AUTOSAR XML (schema 00046)
package /ComponentTypes
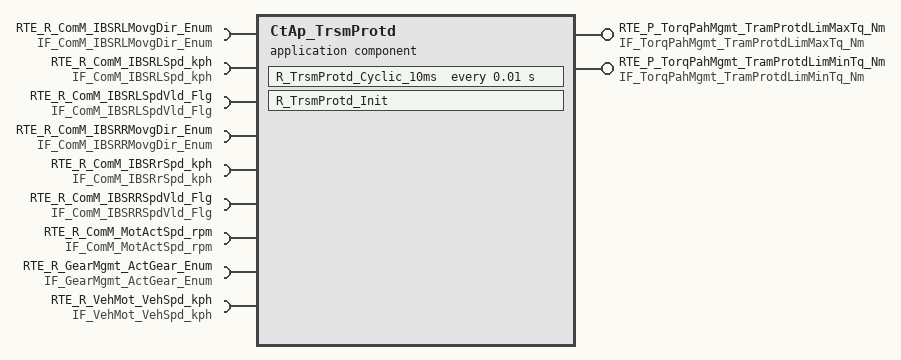
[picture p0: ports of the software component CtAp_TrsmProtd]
  application sw component type CtAp_TrsmProtd
    provide port RTE_P_TorqPahMgmt_TramProtdLimMaxTq_Nm: nonqueued-sender-com-spec=tec_TorqPahMgmt_TramProtdLmtMaxTq_Nm, provided-interface=IF_TorqPahMgmt_TramProtdLimMaxTq_Nm
    provide port RTE_P_TorqPahMgmt_TramProtdLimMinTq_Nm: nonqueued-sender-com-spec=tec_TorqPahMgmt_TramProtdLmtMinTq_Nm, provided-interface=IF_TorqPahMgmt_TramProtdLimMinTq_Nm
    9 x require port:
      RTE_R_ComM_IBSRLMovgDir_Enum: nonqueued-receiver-com-spec{data-element=tec_ComM_IBSRLMovgDir_Enum, filter=data-filter-type=ALWAYS}, required-interface=IF_ComM_IBSRLMovgDir_Enum
      RTE_R_ComM_IBSRLSpd_kph: nonqueued-receiver-com-spec{data-element=tec_ComM_IBSRLSpd_kph, filter=data-filter-type=ALWAYS}, required-interface=IF_ComM_IBSRLSpd_kph
      RTE_R_ComM_IBSRLSpdVld_Flg: nonqueued-receiver-com-spec{data-element=tec_ComM_IBSRLSpdVld_Flg, filter=data-filter-type=ALWAYS}, required-interface=IF_ComM_IBSRLSpdVld_Flg
      RTE_R_ComM_IBSRRMovgDir_Enum: nonqueued-receiver-com-spec{data-element=tec_ComM_IBSRRMovgDir_Enum, filter=data-filter-type=ALWAYS}, required-interface=IF_ComM_IBSRRMovgDir_Enum
      RTE_R_ComM_IBSRrSpd_kph: nonqueued-receiver-com-spec{data-element=tec_ComM_IBSRRSpd_kph, filter=data-filter-type=ALWAYS}, required-interface=IF_ComM_IBSRrSpd_kph
      RTE_R_ComM_IBSRRSpdVld_Flg: nonqueued-receiver-com-spec{data-element=tec_ComM_IBSRRSpdVld_Flg, filter=data-filter-type=ALWAYS}, required-interface=IF_ComM_IBSRRSpdVld_Flg
      RTE_R_ComM_MotActSpd_rpm: nonqueued-receiver-com-spec{data-element=tec_ComM_MotActSpd_rpm, filter=data-filter-type=ALWAYS}, required-interface=IF_ComM_MotActSpd_rpm
      RTE_R_GearMgmt_ActGear_Enum: nonqueued-receiver-com-spec{data-element=tec_GearMgmt_ActGear_Enum, filter=data-filter-type=ALWAYS}, required-interface=IF_GearMgmt_ActGear_Enum
      RTE_R_VehMot_VehSpd_kph: nonqueued-receiver-com-spec{data-element=tec_VehMot_VehSpd_kph, filter=data-filter-type=ALWAYS}, required-interface=IF_VehMot_VehSpd_kph
    behavior CtAp_TrsmProtd_InternalBehavior
      timing event TMT_R_TrsmProtd_Cyclic_10ms: start-on-event=R_TrsmProtd_Cyclic_10ms, period=0.01
      init event CtAp_TrsmProtd_InitEvent: start-on-event=R_TrsmProtd_Init
      runnable R_TrsmProtd_Cyclic_10ms
        data-receive-point-by-arguments:
          9 x access:
            REC_RTE_R_ComM_IBSRLMovgDir_Enum_tec_ComM_IBSRLMovgDir_Enum: accessed-variable=RTE_R_ComM_IBSRLMovgDir_Enum.tec_ComM_IBSRLMovgDir_Enum
            REC_RTE_R_ComM_IBSRLSpd_kph_tec_ComM_IBSRLSpd_kph: accessed-variable=RTE_R_ComM_IBSRLSpd_kph.tec_ComM_IBSRLSpd_kph
            REC_RTE_R_Comm_IBSRLSpdVld_Flg_tec_ComM_IBSRLSpdVld_Flg: accessed-variable=RTE_R_ComM_IBSRLSpdVld_Flg.tec_ComM_IBSRLSpdVld_Flg
            REC_RTE_R_ComM_IBSRRMovgDir_Enum_tec_ComM_IBSRRMovgDir_Enum: accessed-variable=RTE_R_ComM_IBSRRMovgDir_Enum.tec_ComM_IBSRRMovgDir_Enum
            REC_RTE_R_Comm_IBSRrSpd_kph_tec_ComM_IBSRRSpd_kph: accessed-variable=RTE_R_ComM_IBSRrSpd_kph.tec_ComM_IBSRRSpd_kph
            REC_RTE_R_Comm_IBSRRSpdVld_Flg_tec_ComM_IBSRRSpdVld_Flg: accessed-variable=RTE_R_ComM_IBSRRSpdVld_Flg.tec_ComM_IBSRRSpdVld_Flg
            REC_RTE_R_ComM_MotActSpd_rpm_tec_ComM_MotActSpd_rpm: accessed-variable=RTE_R_ComM_MotActSpd_rpm.tec_ComM_MotActSpd_rpm
            REC_RTE_R_GearMgmt_ActGear_Enum_tec_GearMgmt_ActGear_Enum: accessed-variable=RTE_R_GearMgmt_ActGear_Enum.tec_GearMgmt_ActGear_Enum
            REC_RTE_R_VehMot_VehSpd_kph_tec_VehMot_VehSpd_kph: accessed-variable=RTE_R_VehMot_VehSpd_kph.tec_VehMot_VehSpd_kph
        data-send-points:
          access SEND_RTE_P_TorqPahMgmt_TramProtdLimMaxTq_Nm_tec_TorqPahMgmt_TramProtdLmtMaxTq_Nm: accessed-variable=RTE_P_TorqPahMgmt_TramProtdLimMaxTq_Nm.tec_TorqPahMgmt_TramProtdLmtMaxTq_Nm
          access SEND_RTE_P_TorqPahMgmt_TramProtdLimMinTq_Nm_tec_TorqPahMgmt_TramProtdLmtMinTq_Nm: accessed-variable=RTE_P_TorqPahMgmt_TramProtdLimMinTq_Nm.tec_TorqPahMgmt_TramProtdLmtMinTq_Nm
      runnable R_TrsmProtd_Init
  swc implementation CtAp_TrsmProtd_Implementation: behavior=CtAp_TrsmProtd_InternalBehavior
    code-descriptors:
      code Default: artifact-descriptors=autosar-engineering-object={short-label=Default, category=SWOBJ}
